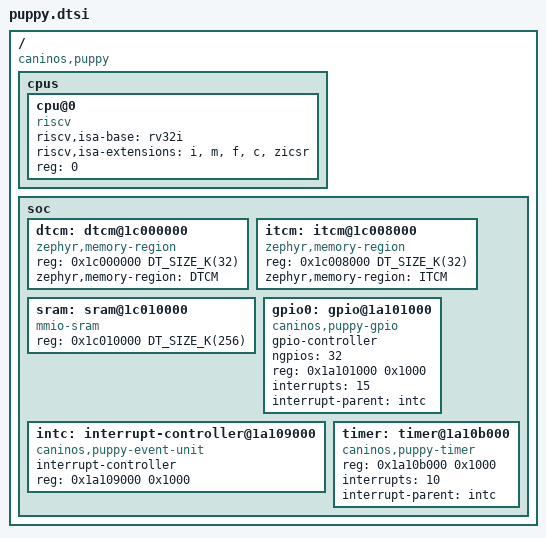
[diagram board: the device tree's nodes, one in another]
/dts-v1/;

#include <freq.h>
#include <mem.h>
#include "zephyr/dt-bindings/gpio/gpio.h"

/ {
	#address-cells = <1>;
	#size-cells = <1>;
	compatible = "caninos,puppy";

	cpus {
		#address-cells = <1>;
		#size-cells = <0>;

		cpu@0 {
			device_type = "cpu";
			status = "okay";
			compatible = "riscv";
			riscv,isa-base = "rv32i";
			riscv,isa-extensions = "i", "m", "f", "c", "zicsr";
			reg = <0>;
		};
	};

	soc: soc {
		#address-cells = <1>;
		#size-cells = <1>;

		dtcm: dtcm@1c000000 {
			compatible = "zephyr,memory-region";
			reg = <0x1c000000 DT_SIZE_K(32)>;
			zephyr,memory-region = "DTCM";
		};

		itcm: itcm@1c008000 {
			compatible = "zephyr,memory-region";
			reg = <0x1c008000 DT_SIZE_K(32)>;
			zephyr,memory-region = "ITCM";
		};

		sram: sram@1c010000 {
			compatible = "mmio-sram";
			reg = <0x1c010000 DT_SIZE_K(256)>;
			status = "okay";
		};

		gpio0: gpio@1a101000 {
			compatible = "caninos,puppy-gpio";
			gpio-controller;
			ngpios = <32>;
			reg = <0x1a101000 0x1000>;
			interrupts = <15>;
			interrupt-parent = <&intc>;
			#gpio-cells = <2>;
		};

		intc: interrupt-controller@1a109000 {
			#interrupt-cells = <1>;
			compatible = "caninos,puppy-event-unit";
			interrupt-controller;
			reg = <0x1a109000 0x1000>;
		};

		timer: timer@1a10b000 {
			compatible = "caninos,puppy-timer";
			reg = <0x1a10b000 0x1000>;
			interrupts = <10>;
			interrupt-parent = <&intc>;
		};
	};
};
